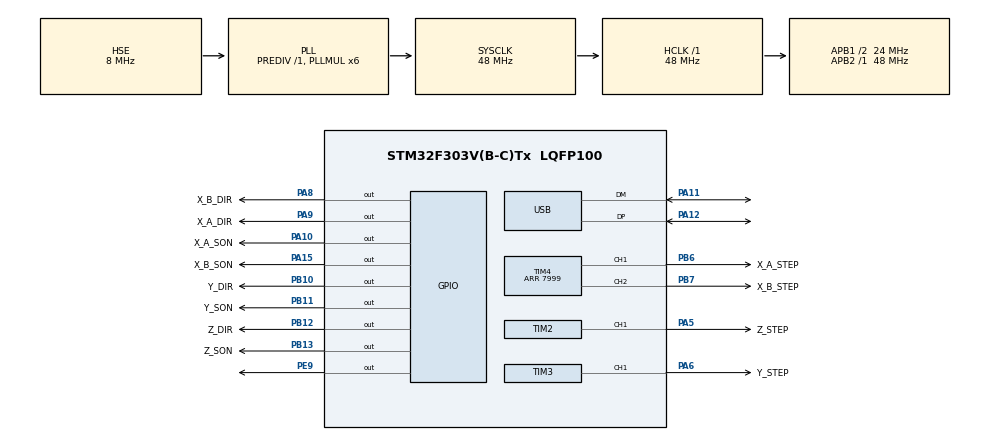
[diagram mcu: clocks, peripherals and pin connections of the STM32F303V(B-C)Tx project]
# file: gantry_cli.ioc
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FREERTOS.Tasks01=defaultTask,24,128,StartDefaultTask,Default,NULL,Dynamic,NULL,NULL
FREERTOS.configUSE_NEWLIB_REENTRANT=1
Mcu.Family=STM32F3
Mcu.Name=STM32F303V(B-C)Tx
Mcu.Package=LQFP100
NVIC.PriorityGroup=NVIC_PRIORITYGROUP_4
NVIC.TIM2_IRQn=true\:5\:0\:false\:false\:true\:true\:true\:true\:true
NVIC.TIM3_IRQn=true\:5\:0\:false\:false\:true\:true\:true\:true\:true
NVIC.TIM4_IRQn=true\:5\:0\:false\:false\:true\:true\:true\:true\:true
NVIC.TIM6_DAC_IRQn=true\:15\:0\:false\:false\:true\:false\:false\:true\:true
NVIC.TimeBase=TIM6_DAC_IRQn
NVIC.TimeBaseIP=TIM6
NVIC.USB_LP_CAN_RX0_IRQn=true\:5\:0\:false\:false\:true\:true\:false\:true\:true
PA10.GPIO_Label=X_A_SON
PA10.Signal=GPIO_Output
PA11.Mode=Device
PA11.Signal=USB_DM
PA12.Mode=Device
PA12.Signal=USB_DP
PA15.GPIO_Label=X_B_SON
PA15.Signal=GPIO_Output
PA5.GPIO_Label=Z_STEP
PA5.Signal=S_TIM2_CH1_ETR
PA6.GPIO_Label=Y_STEP
PA6.Signal=S_TIM3_CH1
PA8.GPIO_Label=X_B_DIR
PA8.Signal=GPIO_Output
PA9.GPIO_Label=X_A_DIR
PA9.Signal=GPIO_Output
PB10.GPIO_Label=Y_DIR
PB10.Signal=GPIO_Output
PB11.GPIO_Label=Y_SON
PB11.Signal=GPIO_Output
PB12.GPIO_Label=Z_DIR
PB12.Signal=GPIO_Output
PB13.GPIO_Label=Z_SON
PB13.Signal=GPIO_Output
PB6.GPIO_Label=X_A_STEP
PB6.Signal=S_TIM4_CH1
PB7.GPIO_Label=X_B_STEP
PB7.Signal=S_TIM4_CH2
PE9.Signal=GPIO_Output
PF0-OSC_IN.Mode=HSE-External-Oscillator
PF0-OSC_IN.Signal=RCC_OSC_IN
PF1-OSC_OUT.Mode=HSE-External-Oscillator
PF1-OSC_OUT.Signal=RCC_OSC_OUT
ProjectManager.HeapSize=0x200
ProjectManager.StackSize=0x400
ProjectManager.TargetToolchain=CMake
RCC.AHBFreq_Value=48000000
RCC.APB1CLKDivider=RCC_HCLK_DIV2
RCC.APB1Freq_Value=24000000
RCC.APB1TimFreq_Value=48000000
RCC.APB2Freq_Value=48000000
RCC.APB2TimFreq_Value=48000000
RCC.CortexFreq_Value=48000000
RCC.HCLKFreq_Value=48000000
RCC.HSE_VALUE=8000000
RCC.HSI_VALUE=8000000
RCC.LSE_VALUE=32768
RCC.PLLMUL=RCC_PLL_MUL6
RCC.SYSCLKFreq_VALUE=48000000
RCC.SYSCLKSourceVirtual=RCC_SYSCLKSOURCE_PLLCLK
RCC.USBFreq_Value=48000000
SH.S_TIM2_CH1_ETR.0=TIM2_CH1,PWM Generation1 CH1
SH.S_TIM3_CH1.0=TIM3_CH1,PWM Generation1 CH1
SH.S_TIM4_CH1.0=TIM4_CH1,PWM Generation1 CH1
SH.S_TIM4_CH2.0=TIM4_CH2,PWM Generation2 CH2
TIM2.Channel-PWM\ Generation1\ CH1=TIM_CHANNEL_1
TIM3.Channel-PWM\ Generation1\ CH1=TIM_CHANNEL_1
TIM4.AutoReloadPreload=TIM_AUTORELOAD_PRELOAD_ENABLE
TIM4.Channel-PWM\ Generation1\ CH1=TIM_CHANNEL_1
TIM4.Channel-PWM\ Generation2\ CH2=TIM_CHANNEL_2
TIM4.Period=7999
USB_DEVICE.CLASS_NAME_FS=CDC
USB_DEVICE.VirtualMode=Cdc
USB_DEVICE.VirtualModeFS=Cdc_FS
VP_FREERTOS_VS_CMSIS_V2.Mode=CMSIS_V2
VP_SYS_VS_tim6.Mode=TIM6
VP_TIM2_VS_ClockSourceINT.Mode=Internal
VP_TIM3_VS_ClockSourceINT.Mode=Internal
VP_TIM4_VS_ClockSourceINT.Mode=Internal
VP_USB_DEVICE_VS_USB_DEVICE_CDC_FS.Mode=CDC_FS
board=STM32F3DISCOVERY

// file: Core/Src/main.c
/* USER CODE BEGIN Header */
/**
  ******************************************************************************
  * @file           : main.c
  * @brief          : Main program body
  ******************************************************************************
  * @attention
  *
  * Copyright (c) 2026 STMicroelectronics.
  * All rights reserved.
  *
  * This software is licensed under terms that can be found in the LICENSE file
  * in the root directory of this software component.
  * If no LICENSE file comes with this software, it is provided AS-IS.
  *
  ******************************************************************************
  */
/* USER CODE END Header */
#include "main.h"
#include "cmsis_os.h"
#include "tim.h"
#include "usb_device.h"
#include "gpio.h"

/* USER CODE BEGIN Includes */
#include "motor.h"
/* USER CODE END Includes */

void SystemClock_Config(void);
void MX_FREERTOS_Init(void);

int main(void)
{

  /* MCU Configuration--------------------------------------------------------*/

  /* Reset of all peripherals, Initializes the Flash interface and the Systick. */
  HAL_Init();

  /* Configure the system clock */
  SystemClock_Config();

  /* Initialize all configured peripherals */
  MX_GPIO_Init();
  MX_TIM4_Init();
  MX_TIM2_Init();
  MX_TIM3_Init();
  /* USER CODE BEGIN 2 */
  /* Motor timers and SON/DIR pins are owned by axes.c — no boot-time setup here. */
  /* USER CODE END 2 */

  /* Init scheduler */
  osKernelInitialize();  /* Call init function for freertos objects (in cmsis_os2.c) */
  MX_FREERTOS_Init();

  /* Start scheduler */
  osKernelStart();

  /* We should never get here as control is now taken by the scheduler */

  /* Infinite loop */
  while (1)
  {

  }
}

void SystemClock_Config(void)
{
  RCC_OscInitTypeDef RCC_OscInitStruct = {0};
  RCC_ClkInitTypeDef RCC_ClkInitStruct = {0};
  RCC_PeriphCLKInitTypeDef PeriphClkInit = {0};

  /** Initializes the RCC Oscillators according to the specified parameters
  * in the RCC_OscInitTypeDef structure.
  */
  RCC_OscInitStruct.OscillatorType = RCC_OSCILLATORTYPE_HSE;
  RCC_OscInitStruct.HSEState = RCC_HSE_ON;
  RCC_OscInitStruct.HSEPredivValue = RCC_HSE_PREDIV_DIV1;
  RCC_OscInitStruct.HSIState = RCC_HSI_ON;
  RCC_OscInitStruct.PLL.PLLState = RCC_PLL_ON;
  RCC_OscInitStruct.PLL.PLLSource = RCC_PLLSOURCE_HSE;
  RCC_OscInitStruct.PLL.PLLMUL = RCC_PLL_MUL6;
  if (HAL_RCC_OscConfig(&RCC_OscInitStruct) != HAL_OK)
  {
    Error_Handler();
  }

  /** Initializes the CPU, AHB and APB buses clocks
  */
  RCC_ClkInitStruct.ClockType = RCC_CLOCKTYPE_HCLK|RCC_CLOCKTYPE_SYSCLK
                              |RCC_CLOCKTYPE_PCLK1|RCC_CLOCKTYPE_PCLK2;
  RCC_ClkInitStruct.SYSCLKSource = RCC_SYSCLKSOURCE_PLLCLK;
  RCC_ClkInitStruct.AHBCLKDivider = RCC_SYSCLK_DIV1;
  RCC_ClkInitStruct.APB1CLKDivider = RCC_HCLK_DIV2;
  RCC_ClkInitStruct.APB2CLKDivider = RCC_HCLK_DIV1;

  if (HAL_RCC_ClockConfig(&RCC_ClkInitStruct, FLASH_LATENCY_1) != HAL_OK)
  {
    Error_Handler();
  }
  PeriphClkInit.PeriphClockSelection = RCC_PERIPHCLK_USB;
  PeriphClkInit.USBClockSelection = RCC_USBCLKSOURCE_PLL;
  if (HAL_RCCEx_PeriphCLKConfig(&PeriphClkInit) != HAL_OK)
  {
    Error_Handler();
  }
}

void HAL_TIM_PeriodElapsedCallback(TIM_HandleTypeDef *htim)
{
  if (htim->Instance == TIM6)
  {
    HAL_IncTick();
  }
  /* USER CODE BEGIN Callback 1 */
  motor_irq_dispatch(htim);
  /* USER CODE END Callback 1 */
}

void Error_Handler(void)
{
  __disable_irq();
  while (1)
  {
  }
}
